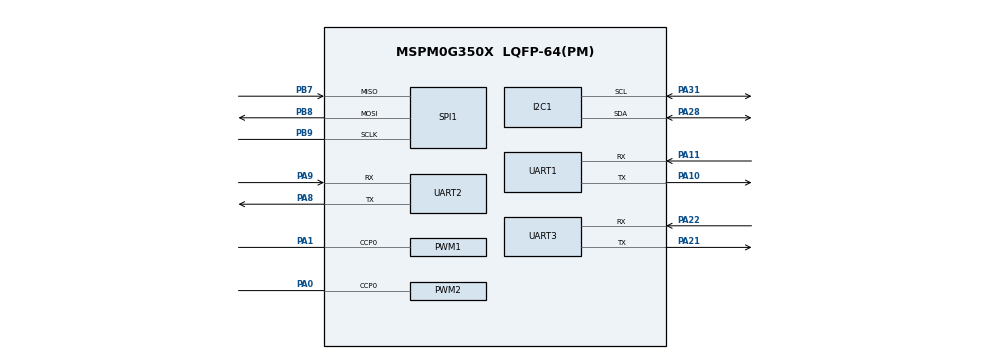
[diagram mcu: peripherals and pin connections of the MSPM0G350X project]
/**
 * @cliArgs --device "MSPM0G350X" --part "Default" --package "LQFP-64(PM)" --product "mspm0_sdk@2.10.00.04"
 * @versions {"tool":"1.26.2+4477"}
 */

/**
 * Import the modules used in this configuration.
 */
const GPIO   = scripting.addModule("/ti/driverlib/GPIO", {}, false);
const GPIO1  = GPIO.addInstance();
const GPIO2  = GPIO.addInstance();
const GPIO3  = GPIO.addInstance();
const GPIO4  = GPIO.addInstance();
const GPIO5  = GPIO.addInstance();
const GPIO6  = GPIO.addInstance();
const GPIO7  = GPIO.addInstance();
const GPIO8  = GPIO.addInstance();
const I2C    = scripting.addModule("/ti/driverlib/I2C", {}, false);
const I2C1   = I2C.addInstance();
const PWM    = scripting.addModule("/ti/driverlib/PWM", {}, false);
const PWM1   = PWM.addInstance();
const PWM2   = PWM.addInstance();
const SPI    = scripting.addModule("/ti/driverlib/SPI", {}, false);
const SPI1   = SPI.addInstance();
const SYSCTL = scripting.addModule("/ti/driverlib/SYSCTL");
const TIMER  = scripting.addModule("/ti/driverlib/TIMER", {}, false);
const TIMER1 = TIMER.addInstance();
const UART   = scripting.addModule("/ti/driverlib/UART", {}, false);
const UART1  = UART.addInstance();
const UART2  = UART.addInstance();
const UART3  = UART.addInstance();

/**
 * Write custom configuration values to the imported modules.
 */
const divider7       = system.clockTree["PLL_PDIV"];
divider7.divideValue = 2;

const divider9       = system.clockTree["UDIV"];
divider9.divideValue = 2;

const multiplier2         = system.clockTree["PLL_QDIV"];
multiplier2.multiplyValue = 5;

const mux8       = system.clockTree["HSCLKMUX"];
mux8.inputSelect = "HSCLKMUX_SYSPLL2X";

const pinFunction4     = system.clockTree["HFXT"];
pinFunction4.inputFreq = 40;

GPIO1.$name                              = "KEY1";
GPIO1.associatedPins[0].direction        = "INPUT";
GPIO1.associatedPins[0].internalResistor = "PULL_UP";
GPIO1.associatedPins[0].assignedPort     = "PORTB";
GPIO1.associatedPins[0].assignedPin      = "0";
GPIO1.associatedPins[0].$name            = "KEY_1";

const Board = scripting.addModule("/ti/driverlib/Board", {}, false);

GPIO2.$name                              = "KEY2";
GPIO2.associatedPins[0].direction        = "INPUT";
GPIO2.associatedPins[0].internalResistor = "PULL_UP";
GPIO2.associatedPins[0].assignedPort     = "PORTA";
GPIO2.associatedPins[0].assignedPin      = "2";
GPIO2.associatedPins[0].$name            = "KEY_2";

GPIO3.$name                              = "KEY3";
GPIO3.associatedPins[0].direction        = "INPUT";
GPIO3.associatedPins[0].internalResistor = "PULL_UP";
GPIO3.associatedPins[0].$name            = "KEY_3";
GPIO3.associatedPins[0].assignedPort     = "PORTB";
GPIO3.associatedPins[0].assignedPin      = "16";

GPIO4.$name                              = "LED";
GPIO4.port                               = "PORTB";
GPIO4.associatedPins.create(2);
GPIO4.associatedPins[0].internalResistor = "PULL_UP";
GPIO4.associatedPins[0].assignedPin      = "25";
GPIO4.associatedPins[0].$name            = "LED3";
GPIO4.associatedPins[1].$name            = "LED4";
GPIO4.associatedPins[1].assignedPin      = "26";
GPIO4.associatedPins[1].internalResistor = "PULL_UP";

GPIO5.$name                              = "BUZZER";
GPIO5.port                               = "PORTB";
GPIO5.associatedPins[0].assignedPin      = "13";
GPIO5.associatedPins[0].internalResistor = "PULL_DOWN";
GPIO5.associatedPins[0].$name            = "buzzer";

GPIO6.$name                          = "CS";
GPIO6.associatedPins[0].$name        = "PIN_7";
GPIO6.associatedPins[0].assignedPort = "PORTB";
GPIO6.associatedPins[0].assignedPin  = "6";

GPIO7.$name                          = "INT1";
GPIO7.associatedPins[0].$name        = "PIN_8";
GPIO7.associatedPins[0].direction    = "INPUT";
GPIO7.associatedPins[0].assignedPort = "PORTB";
GPIO7.associatedPins[0].assignedPin  = "11";
GPIO7.associatedPins[0].interruptEn  = true;
GPIO7.associatedPins[0].polarity     = "RISE";

GPIO8.$name                          = "STEP_MOTOR";
GPIO8.associatedPins.create(4);
GPIO8.associatedPins[0].$name        = "DIR2";
GPIO8.associatedPins[0].assignedPort = "PORTA";
GPIO8.associatedPins[0].assignedPin  = "13";
GPIO8.associatedPins[1].$name        = "DIR1";
GPIO8.associatedPins[1].assignedPort = "PORTA";
GPIO8.associatedPins[1].assignedPin  = "12";
GPIO8.associatedPins[2].$name        = "EN1";
GPIO8.associatedPins[2].assignedPort = "PORTB";
GPIO8.associatedPins[2].assignedPin  = "22";
GPIO8.associatedPins[3].assignedPort = "PORTB";
GPIO8.associatedPins[3].assignedPin  = "23";
GPIO8.associatedPins[3].$name        = "EN2";

I2C1.$name                             = "I2C_OLED";
I2C1.basicEnableController             = true;
I2C1.basicControllerStandardBusSpeed   = "Fast";
I2C1.peripheral.sdaPin.$assign         = "PA28";
I2C1.peripheral.sclPin.$assign         = "PA31";
I2C1.sdaPinConfig.hideOutputInversion  = scripting.forceWrite(false);
I2C1.sdaPinConfig.onlyInternalResistor = scripting.forceWrite(false);
I2C1.sdaPinConfig.passedPeripheralType = scripting.forceWrite("Digital");
I2C1.sdaPinConfig.$name                = "ti_driverlib_gpio_GPIOPinGeneric6";
I2C1.sclPinConfig.hideOutputInversion  = scripting.forceWrite(false);
I2C1.sclPinConfig.onlyInternalResistor = scripting.forceWrite(false);
I2C1.sclPinConfig.passedPeripheralType = scripting.forceWrite("Digital");
I2C1.sclPinConfig.$name                = "ti_driverlib_gpio_GPIOPinGeneric7";

PWM1.$name                              = "DCC_100_PWM1";
PWM1.timerCount                         = 20000;
PWM1.pwmMode                            = "EDGE_ALIGN_UP";
PWM1.interrupts                         = ["LOAD_EVENT"];
PWM1.clockDivider                       = 4;
PWM1.ccIndex                            = [0];
PWM1.PWM_CHANNEL_0.$name                = "ti_driverlib_pwm_PWMTimerCC1";
PWM1.ccp0PinConfig.direction            = scripting.forceWrite("OUTPUT");
PWM1.ccp0PinConfig.hideOutputInversion  = scripting.forceWrite(false);
PWM1.ccp0PinConfig.onlyInternalResistor = scripting.forceWrite(false);
PWM1.ccp0PinConfig.passedPeripheralType = scripting.forceWrite("Digital");
PWM1.ccp0PinConfig.$name                = "ti_driverlib_gpio_GPIOPinGeneric1";
PWM1.peripheral.$assign                 = "TIMG8";
PWM1.peripheral.ccp0Pin.$assign         = "PA1";

PWM2.$name                              = "DCC_100_PWM2";
PWM2.clockDivider                       = 8;
PWM2.timerCount                         = 20000;
PWM2.ccIndex                            = [0];
PWM2.PWM_CHANNEL_0.$name                = "ti_driverlib_pwm_PWMTimerCC2";
PWM2.ccp0PinConfig.$name                = "ti_driverlib_gpio_GPIOPinGeneric4";
PWM2.ccp0PinConfig.direction            = scripting.forceWrite("OUTPUT");
PWM2.ccp0PinConfig.hideOutputInversion  = scripting.forceWrite(false);
PWM2.ccp0PinConfig.onlyInternalResistor = scripting.forceWrite(false);
PWM2.ccp0PinConfig.passedPeripheralType = scripting.forceWrite("Digital");
PWM2.peripheral.$assign                 = "TIMA0";
PWM2.peripheral.ccp0Pin.$assign         = "PA0";

SPI1.$name                      = "SPI_0";
SPI1.frameFormat                = "MOTO3";
SPI1.sclkPinConfig.$name        = "ti_driverlib_gpio_GPIOPinGeneric11";
SPI1.mosiPinConfig.$name        = "ti_driverlib_gpio_GPIOPinGeneric12";
SPI1.misoPinConfig.$name        = "ti_driverlib_gpio_GPIOPinGeneric13";
SPI1.peripheral.sclkPin.$assign = "PB9";
SPI1.peripheral.mosiPin.$assign = "PB8";
SPI1.peripheral.misoPin.$assign = "PB7";

SYSCTL.forceDefaultClkConfig = true;
SYSCTL.clockTreeEn           = true;

TIMER1.$name              = "TIMER_xunji_pid";
TIMER1.timerClkPrescale   = 100;
TIMER1.timerStartTimer    = true;
TIMER1.interrupts         = ["ZERO"];
TIMER1.timerMode          = "PERIODIC";
TIMER1.timerPeriod        = "1 ms";
TIMER1.peripheral.$assign = "TIMG7";

UART1.$name                    = "UART_0";
UART1.targetBaudRate           = 115200;
UART1.peripheral.$assign       = "UART0";
UART1.peripheral.rxPin.$assign = "PA11";
UART1.peripheral.txPin.$assign = "PA10";
UART1.txPinConfig.$name        = "ti_driverlib_gpio_GPIOPinGeneric2";
UART1.rxPinConfig.$name        = "ti_driverlib_gpio_GPIOPinGeneric3";

UART2.enabledInterrupts                = ["RX"];
UART2.$name                            = "UART1_SENSOR";
UART2.targetBaudRate                   = 115200;
UART2.peripheral.$assign               = "UART1";
UART2.peripheral.rxPin.$assign         = "PA9";
UART2.peripheral.txPin.$assign         = "PA8";
UART2.txPinConfig.direction            = scripting.forceWrite("OUTPUT");
UART2.txPinConfig.hideOutputInversion  = scripting.forceWrite(false);
UART2.txPinConfig.onlyInternalResistor = scripting.forceWrite(false);
UART2.txPinConfig.passedPeripheralType = scripting.forceWrite("Digital");
UART2.txPinConfig.$name                = "ti_driverlib_gpio_GPIOPinGeneric9";
UART2.rxPinConfig.hideOutputInversion  = scripting.forceWrite(false);
UART2.rxPinConfig.onlyInternalResistor = scripting.forceWrite(false);
UART2.rxPinConfig.passedPeripheralType = scripting.forceWrite("Digital");
UART2.rxPinConfig.$name                = "ti_driverlib_gpio_GPIOPinGeneric10";

UART3.targetBaudRate                   = 115200;
UART3.$name                            = "vision";
UART3.peripheral.$assign               = "UART2";
UART3.peripheral.rxPin.$assign         = "PA22";
UART3.peripheral.txPin.$assign         = "PA21";
UART3.txPinConfig.direction            = scripting.forceWrite("OUTPUT");
UART3.txPinConfig.hideOutputInversion  = scripting.forceWrite(false);
UART3.txPinConfig.onlyInternalResistor = scripting.forceWrite(false);
UART3.txPinConfig.passedPeripheralType = scripting.forceWrite("Digital");
UART3.txPinConfig.$name                = "ti_driverlib_gpio_GPIOPinGeneric14";
UART3.rxPinConfig.hideOutputInversion  = scripting.forceWrite(false);
UART3.rxPinConfig.onlyInternalResistor = scripting.forceWrite(false);
UART3.rxPinConfig.passedPeripheralType = scripting.forceWrite("Digital");
UART3.rxPinConfig.$name                = "ti_driverlib_gpio_GPIOPinGeneric15";

/**
 * Pinmux solution for unlocked pins/peripherals. This ensures that minor changes to the automatic solver in a future
 * version of the tool will not impact the pinmux you originally saw.  These lines can be completely deleted in order to
 * re-solve from scratch.
 */
GPIO1.associatedPins[0].pin.$suggestSolution = "PB0";
Board.peripheral.$suggestSolution            = "DEBUGSS";
Board.peripheral.swclkPin.$suggestSolution   = "PA20";
Board.peripheral.swdioPin.$suggestSolution   = "PA19";
GPIO2.associatedPins[0].pin.$suggestSolution = "PA2";
GPIO3.associatedPins[0].pin.$suggestSolution = "PB16";
GPIO4.associatedPins[0].pin.$suggestSolution = "PB25";
GPIO4.associatedPins[1].pin.$suggestSolution = "PB26";
GPIO5.associatedPins[0].pin.$suggestSolution = "PB13";
GPIO6.associatedPins[0].pin.$suggestSolution = "PB6";
GPIO7.associatedPins[0].pin.$suggestSolution = "PB11";
GPIO8.associatedPins[0].pin.$suggestSolution = "PA13";
GPIO8.associatedPins[1].pin.$suggestSolution = "PA12";
GPIO8.associatedPins[2].pin.$suggestSolution = "PB22";
GPIO8.associatedPins[3].pin.$suggestSolution = "PB23";
I2C1.peripheral.$suggestSolution             = "I2C0";
SPI1.peripheral.$suggestSolution             = "SPI1";
